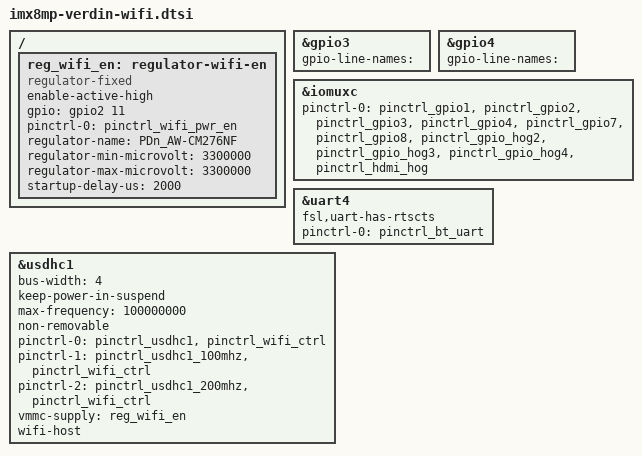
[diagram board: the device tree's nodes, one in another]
// SPDX-License-Identifier: GPL-2.0+ OR MIT
/*
 * Copyright 2020 Toradex
 */

/ {
	reg_wifi_en: regulator-wifi-en {
		compatible = "regulator-fixed";
		enable-active-high;
		gpio = <&gpio2 11 GPIO_ACTIVE_HIGH>;
		pinctrl-names = "default";
		pinctrl-0 = <&pinctrl_wifi_pwr_en>;
		regulator-name = "PDn_AW-CM276NF";
		regulator-min-microvolt = <3300000>;
		regulator-max-microvolt = <3300000>;
		startup-delay-us = <2000>;
	};
};

&gpio3 {
	gpio-line-names = "";
};

&gpio4 {
	gpio-line-names = "";
};

&iomuxc {
	pinctrl-names = "default";
	pinctrl-0 = <&pinctrl_gpio1>, <&pinctrl_gpio2>,
		    <&pinctrl_gpio3>, <&pinctrl_gpio4>,
		    <&pinctrl_gpio7>, <&pinctrl_gpio8>,
		    <&pinctrl_gpio_hog2>, <&pinctrl_gpio_hog3>, <&pinctrl_gpio_hog4>,
		    <&pinctrl_hdmi_hog>;
};

/* On-module Bluetooth */
&uart4 {
	fsl,uart-has-rtscts;
	pinctrl-names = "default";
	pinctrl-0 = <&pinctrl_bt_uart>;
	status = "okay";
};

/* On-module Wi-Fi */
&usdhc1 {
	bus-width = <4>;
	keep-power-in-suspend;
	max-frequency = <100000000>;
	non-removable;
	pinctrl-names = "default", "state_100mhz", "state_200mhz";
	pinctrl-0 = <&pinctrl_usdhc1>, <&pinctrl_wifi_ctrl>;
	pinctrl-1 = <&pinctrl_usdhc1_100mhz>, <&pinctrl_wifi_ctrl>;
	pinctrl-2 = <&pinctrl_usdhc1_200mhz>, <&pinctrl_wifi_ctrl>;
	vmmc-supply = <&reg_wifi_en>;
	wifi-host;
	status = "okay";
};
